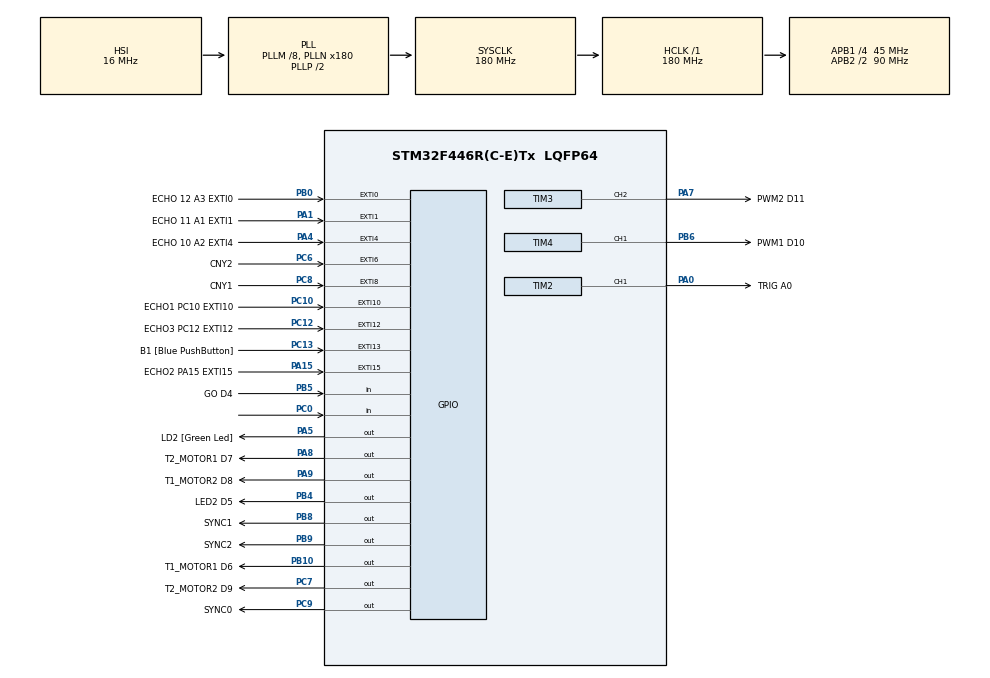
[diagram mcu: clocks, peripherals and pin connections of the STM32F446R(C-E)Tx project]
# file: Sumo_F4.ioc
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Mcu.Family=STM32F4
Mcu.Name=STM32F446R(C-E)Tx
Mcu.Package=LQFP64
NVIC.EXTI0_IRQn=true\:0\:0\:false
NVIC.EXTI15_10_IRQn=true\:0\:0\:false
NVIC.EXTI1_IRQn=true\:0\:0\:false
NVIC.EXTI4_IRQn=true\:0\:0\:false
NVIC.EXTI9_5_IRQn=true\:0\:0\:false
NVIC.PriorityGroup=NVIC_PRIORITYGROUP_4
NVIC.TIM1_TRG_COM_TIM11_IRQn=true\:0\:0\:false
NVIC.TIM1_UP_TIM10_IRQn=true\:0\:0\:false
NVIC.TIM8_TRG_COM_TIM14_IRQn=true\:0\:0\:false
NVIC.TIM8_UP_TIM13_IRQn=true\:0\:0\:false
PA0-WKUP.GPIO_Label=TRIG A0
PA0-WKUP.Signal=S_TIM2_CH1_ETR
PA1.GPIO_Label=ECHO 11 A1 EXTI1
PA1.GPIO_ModeDefaultEXTI=GPIO_MODE_IT_FALLING
PA1.Signal=GPXTI1
PA13.GPIO_Label=TMS
PA13.Signal=SYS_JTMS-SWDIO
PA14.GPIO_Label=TCK
PA14.Signal=SYS_JTCK-SWCLK
PA15.GPIO_Label=ECHO2 PA15 EXTI15
PA15.GPIO_ModeDefaultEXTI=GPIO_MODE_IT_FALLING
PA15.Signal=GPXTI15
PA2.GPIO_Label=USART_TX
PA2.Signal=USART2_TX
PA3.GPIO_Label=USART_RX
PA3.Signal=USART2_RX
PA4.GPIO_Label=ECHO 10 A2 EXTI4
PA4.GPIO_ModeDefaultEXTI=GPIO_MODE_IT_FALLING
PA4.Signal=GPXTI4
PA5.GPIO_Label=LD2 [Green Led]
PA5.Signal=GPIO_Output
PA7.GPIO_Label=PWM2 D11
PA7.Signal=S_TIM3_CH2
PA8.GPIO_Label=T2_MOTOR1 D7
PA8.Signal=GPIO_Output
PA9.GPIO_Label=T1_MOTOR2 D8
PA9.Signal=GPIO_Output
PB0.GPIO_Label=ECHO 12 A3 EXTI0
PB0.GPIO_ModeDefaultEXTI=GPIO_MODE_IT_FALLING
PB0.Signal=GPXTI0
PB10.GPIO_Label=T1_MOTOR1 D6
PB10.Signal=GPIO_Output
PB3.GPIO_Label=SWO
PB3.Signal=SYS_JTDO-SWO
PB4.GPIO_Label=LED2 D5
PB4.Signal=GPIO_Output
PB5.GPIO_Label=GO D4
PB5.Signal=GPIO_Input
PB6.GPIO_Label=PWM1 D10
PB6.Signal=S_TIM4_CH1
PB8.GPIO_Label=SYNC1
PB8.Signal=GPIO_Output
PB9.GPIO_Label=SYNC2
PB9.Signal=GPIO_Output
PC0.Signal=GPIO_Input
PC10.GPIO_Label=ECHO1 PC10 EXTI10
PC10.GPIO_ModeDefaultEXTI=GPIO_MODE_IT_FALLING
PC10.Signal=GPXTI10
PC12.GPIO_Label=ECHO3 PC12 EXTI12
PC12.GPIO_ModeDefaultEXTI=GPIO_MODE_IT_FALLING
PC12.Signal=GPXTI12
PC13.GPIO_Label=B1 [Blue PushButton]
PC13.GPIO_ModeDefaultEXTI=GPIO_MODE_IT_FALLING
PC13.Signal=GPXTI13
PC14-OSC32_IN.Signal=RCC_OSC32_IN
PC15-OSC32_OUT.Signal=RCC_OSC32_OUT
PC6.GPIO_Label=CNY2
PC6.GPIO_ModeDefaultEXTI=GPIO_MODE_IT_RISING_FALLING
PC6.Signal=GPXTI6
PC7.GPIO_Label=T2_MOTOR2 D9
PC7.Signal=GPIO_Output
PC8.GPIO_Label=CNY1
PC8.GPIO_ModeDefaultEXTI=GPIO_MODE_IT_RISING_FALLING
PC8.Signal=GPXTI8
PC9.GPIO_Label=SYNC0
PC9.Signal=GPIO_Output
PH0-OSC_IN.Signal=RCC_OSC_IN
PH1-OSC_OUT.Signal=RCC_OSC_OUT
ProjectManager.HeapSize=0x400
ProjectManager.StackSize=0x200
ProjectManager.TargetToolchain=TrueSTUDIO
RCC.AHBFreq_Value=180000000
RCC.APB1CLKDivider=RCC_HCLK_DIV4
RCC.APB1Freq_Value=45000000
RCC.APB1TimFreq_Value=90000000
RCC.APB2CLKDivider=RCC_HCLK_DIV2
RCC.APB2Freq_Value=90000000
RCC.APB2TimFreq_Value=180000000
RCC.CortexFreq_Value=180000000
RCC.DATA_CACHE_ENABLE=1
RCC.FLatency-AdvancedSettings=FLASH_LATENCY_2
RCC.HCLKFreq_Value=180000000
RCC.HSE_VALUE=8000000
RCC.HSI_VALUE=16000000
RCC.LSE_VALUE=32768
RCC.PLLM=8
RCC.PLLN=180
RCC.SYSCLKFreq_VALUE=180000000
RCC.SYSCLKSource=RCC_SYSCLKSOURCE_PLLCLK
RCC.USBFreq_Value=180000000
RCC.VCOOutputFreq_Value=360000000
SH.S_TIM2_CH1_ETR.0=TIM2_CH1,PWM Generation1 CH1
SH.S_TIM3_CH2.0=TIM3_CH2,PWM Generation2 CH2
SH.S_TIM4_CH1.0=TIM4_CH1,PWM Generation1 CH1
TIM10.OCMode_1=TIM_OCMODE_ACTIVE
TIM10.Period=0xFFFF
TIM10.Prescaler=18000
TIM10.Pulse=10
TIM11.Period=0xFFFF
TIM11.Prescaler=18000
TIM11.Pulse=10
TIM13.Period=0xFFFF
TIM13.Prescaler=18000
TIM13.Pulse=10
TIM14.Period=0xFFFF
TIM14.Prescaler=18000
TIM14.Pulse=10
TIM2.Period=10000
TIM2.Prescaler=90
TIM2.Pulse-PWM\ Generation1\ CH1=20
TIM3.Channel-PWM\ Generation2\ CH2=TIM_CHANNEL_2
TIM3.Period=1000
TIM3.Prescaler=100
TIM3.Pulse-PWM\ Generation2\ CH2=500
TIM4.Period=1000
TIM4.Prescaler=100
TIM4.Pulse-PWM\ Generation1\ CH1=500
TIM5.Period=0xFFFFFFFF
TIM5.Prescaler=90
VP_TIM10_VS_ClockSourceINT.Mode=Enable_Timer
VP_TIM10_VS_OPM.Mode=OPM_bit
VP_TIM10_VS_no_output1.Mode=Output Compare1 No Output
VP_TIM11_VS_ClockSourceINT.Mode=Enable_Timer
VP_TIM11_VS_OPM.Mode=OPM_bit
VP_TIM11_VS_no_output1.Mode=Output Compare1 No Output
VP_TIM13_VS_ClockSourceINT.Mode=Enable_Timer
VP_TIM13_VS_OPM.Mode=OPM_bit
VP_TIM13_VS_no_output1.Mode=Output Compare1 No Output
VP_TIM14_VS_ClockSourceINT.Mode=Enable_Timer
VP_TIM14_VS_OPM.Mode=OPM_bit
VP_TIM14_VS_no_output1.Mode=Output Compare1 No Output
VP_TIM2_VS_ClockSourceINT.Mode=Internal
VP_TIM3_VS_ClockSourceINT.Mode=Internal
VP_TIM4_VS_ClockSourceINT.Mode=Internal
VP_TIM5_VS_ClockSourceINT.Mode=Internal
board=NUCLEO-F446RE

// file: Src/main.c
/**
  ******************************************************************************
  * File Name          : main.c
  * Description        : Main program body
  ******************************************************************************
  *
  * COPYRIGHT(c) 2016 STMicroelectronics
  *
  * Redistribution and use in source and binary forms, with or without modification,
  * are permitted provided that the following conditions are met:
  *   1. Redistributions of source code must retain the above copyright notice,
  *      this list of conditions and the following disclaimer.
  *   2. Redistributions in binary form must reproduce the above copyright notice,
  *      this list of conditions and the following disclaimer in the documentation
  *      and/or other materials provided with the distribution.
  *   3. Neither the name of STMicroelectronics nor the names of its contributors
  *      may be used to endorse or promote products derived from this software
  *      without specific prior written permission.
  *
  * THIS SOFTWARE IS PROVIDED BY THE COPYRIGHT HOLDERS AND CONTRIBUTORS "AS IS"
  * AND ANY EXPRESS OR IMPLIED WARRANTIES, INCLUDING, BUT NOT LIMITED TO, THE
  * IMPLIED WARRANTIES OF MERCHANTABILITY AND FITNESS FOR A PARTICULAR PURPOSE ARE
  * DISCLAIMED. IN NO EVENT SHALL THE COPYRIGHT HOLDER OR CONTRIBUTORS BE LIABLE
  * FOR ANY DIRECT, INDIRECT, INCIDENTAL, SPECIAL, EXEMPLARY, OR CONSEQUENTIAL
  * DAMAGES (INCLUDING, BUT NOT LIMITED TO, PROCUREMENT OF SUBSTITUTE GOODS OR
  * SERVICES; LOSS OF USE, DATA, OR PROFITS; OR BUSINESS INTERRUPTION) HOWEVER
  * CAUSED AND ON ANY THEORY OF LIABILITY, WHETHER IN CONTRACT, STRICT LIABILITY,
  * OR TORT (INCLUDING NEGLIGENCE OR OTHERWISE) ARISING IN ANY WAY OUT OF THE USE
  * OF THIS SOFTWARE, EVEN IF ADVISED OF THE POSSIBILITY OF SUCH DAMAGE.
  *
  ******************************************************************************
  */
#include "stm32f4xx_hal.h"
#include "tim.h"
#include "gpio.h"

/* USER CODE BEGIN Includes */
#include "Sensor.h"
#include "Action.h"

#undef FLASH_LATENCY_2
#define FLASH_LATENCY_2 FLASH_LATENCY_3 // does not work otherwise

/* USER CODE END Includes */

/* USER CODE BEGIN PV */
/* Private variables ---------------------------------------------------------*/

/* USER CODE END PV */

void SystemClock_Config(void);

/* USER CODE BEGIN PFP */
/* Private function prototypes -----------------------------------------------*/

/* USER CODE END PFP */

int main(void)
{

  /* MCU Configuration----------------------------------------------------------*/

  /* Reset of all peripherals, Initializes the Flash interface and the Systick. */
  HAL_Init();

  /* Configure the system clock */
  SystemClock_Config();

  /* Initialize all configured peripherals */
  MX_GPIO_Init();
  MX_TIM2_Init();
  MX_TIM3_Init();
  MX_TIM4_Init();
  MX_TIM5_Init();
  MX_TIM10_Init();
  MX_TIM11_Init();
  MX_TIM13_Init();
  MX_TIM14_Init();

  /* USER CODE BEGIN 2 */

do_initializeControl();

	HAL_TIM_Base_Start(&htim5); // microsecond counter just in case
	HAL_TIM_OC_Start(&htim2, TIM_CHANNEL_1); // ultrasound pulse firing on A0
	HAL_TIM_PWM_Start(&htim4, TIM_CHANNEL_1); // PWM1
	HAL_TIM_PWM_Start(&htim3, TIM_CHANNEL_2); // PWM2

  /* USER CODE END 2 */

  /* Infinite loop */
  /* USER CODE BEGIN WHILE */
  while (1)
  {
	  mainLoop();
  /* USER CODE END WHILE */

  }

}

/** System Clock Configuration
*/
void SystemClock_Config(void)
{

  RCC_OscInitTypeDef RCC_OscInitStruct;
  RCC_ClkInitTypeDef RCC_ClkInitStruct;

  __PWR_CLK_ENABLE();

  __HAL_PWR_VOLTAGESCALING_CONFIG(PWR_REGULATOR_VOLTAGE_SCALE1);

  RCC_OscInitStruct.OscillatorType = RCC_OSCILLATORTYPE_HSI;
  RCC_OscInitStruct.HSIState = RCC_HSI_ON;
  RCC_OscInitStruct.HSICalibrationValue = 16;
  RCC_OscInitStruct.PLL.PLLState = RCC_PLL_ON;
  RCC_OscInitStruct.PLL.PLLSource = RCC_PLLSOURCE_HSI;
  RCC_OscInitStruct.PLL.PLLM = 8;
  RCC_OscInitStruct.PLL.PLLN = 180;
  RCC_OscInitStruct.PLL.PLLP = RCC_PLLP_DIV2;
  RCC_OscInitStruct.PLL.PLLQ = 2;
  RCC_OscInitStruct.PLL.PLLR = 2;
  HAL_RCC_OscConfig(&RCC_OscInitStruct);

  HAL_PWREx_ActivateOverDrive();

  RCC_ClkInitStruct.ClockType = RCC_CLOCKTYPE_HCLK|RCC_CLOCKTYPE_SYSCLK
                              |RCC_CLOCKTYPE_PCLK1|RCC_CLOCKTYPE_PCLK2;
  RCC_ClkInitStruct.SYSCLKSource = RCC_SYSCLKSOURCE_PLLCLK;
  RCC_ClkInitStruct.AHBCLKDivider = RCC_SYSCLK_DIV1;
  RCC_ClkInitStruct.APB1CLKDivider = RCC_HCLK_DIV4;
  RCC_ClkInitStruct.APB2CLKDivider = RCC_HCLK_DIV2;
  HAL_RCC_ClockConfig(&RCC_ClkInitStruct, FLASH_LATENCY_2);

  HAL_SYSTICK_Config(HAL_RCC_GetHCLKFreq()/1000);

  HAL_SYSTICK_CLKSourceConfig(SYSTICK_CLKSOURCE_HCLK);

  /* SysTick_IRQn interrupt configuration */
  HAL_NVIC_SetPriority(SysTick_IRQn, 0, 0);
}

/************************ (C) COPYRIGHT STMicroelectronics *****END OF FILE****/
